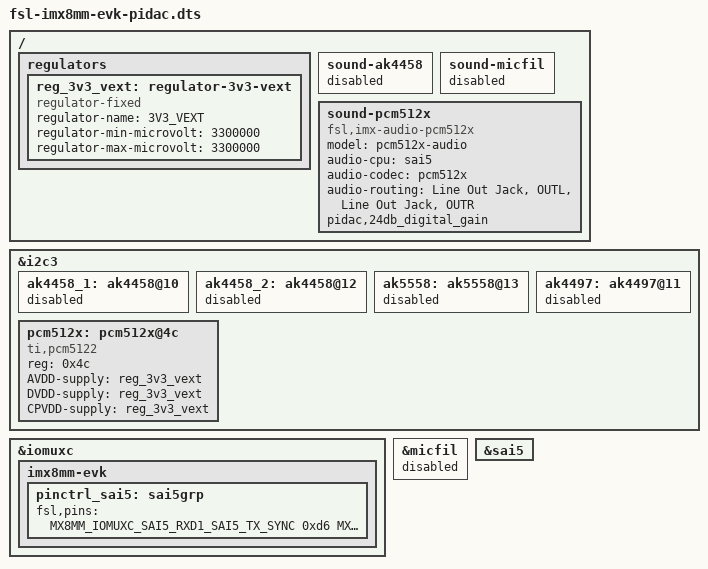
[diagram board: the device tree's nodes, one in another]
/*
 * Copyright 2020 NXP
 *
 * This program is free software; you can redistribute it and/or
 * modify it under the terms of the GNU General Public License
 * as published by the Free Software Foundation; either version 2
 * of the License, or (at your option) any later version.
 *
 * This program is distributed in the hope that it will be useful,
 * but WITHOUT ANY WARRANTY; without even the implied warranty of
 * MERCHANTABILITY or FITNESS FOR A PARTICULAR PURPOSE.  See the
 * GNU General Public License for more details.
 */

#include "fsl-imx8mm-evk.dts"

/ {
	regulators {
		reg_3v3_vext: regulator-3v3-vext {
			compatible = "regulator-fixed";
			regulator-name = "3V3_VEXT";
			regulator-min-microvolt = <3300000>;
			regulator-max-microvolt = <3300000>;
		};
	};

	sound-ak4458 {
		status = "disabled";
	};

	sound-micfil {
		status = "disabled";
	};

	sound-pcm512x {
		compatible = "fsl,imx-audio-pcm512x";
		model = "pcm512x-audio";
		audio-cpu = <&sai5>;
		audio-codec = <&pcm512x>;
		audio-routing =
			"Line Out Jack", "OUTL",
			"Line Out Jack", "OUTR";
		pidac,24db_digital_gain;
	};
};

&i2c3 {
	ak4458_1: ak4458@10 {
		status = "disabled";
	};

	ak4458_2: ak4458@12 {
		status = "disabled";
	};

	ak5558: ak5558@13 {
		status = "disabled";
	};

	ak4497: ak4497@11 {
		status = "disabled";
	};

	pcm512x: pcm512x@4c {
		compatible = "ti,pcm5122";
		reg = <0x4c>;
		AVDD-supply = <&reg_3v3_vext>;
		DVDD-supply = <&reg_3v3_vext>;
		CPVDD-supply = <&reg_3v3_vext>;
		status = "okay";
	};
};

&iomuxc {
	imx8mm-evk {
		pinctrl_sai5: sai5grp {
			fsl,pins = <
				MX8MM_IOMUXC_SAI5_RXD1_SAI5_TX_SYNC	0xd6
				MX8MM_IOMUXC_SAI5_RXD2_SAI5_TX_BCLK	0xd6
				MX8MM_IOMUXC_SAI5_RXD3_SAI5_TX_DATA0	0xd6
				MX8MM_IOMUXC_SAI5_RXD0_SAI5_RX_DATA0	0xd6
			>;
		};
	};
};

&micfil {
	status = "disabled";
};

&sai5 {
	status = "okay";
};
